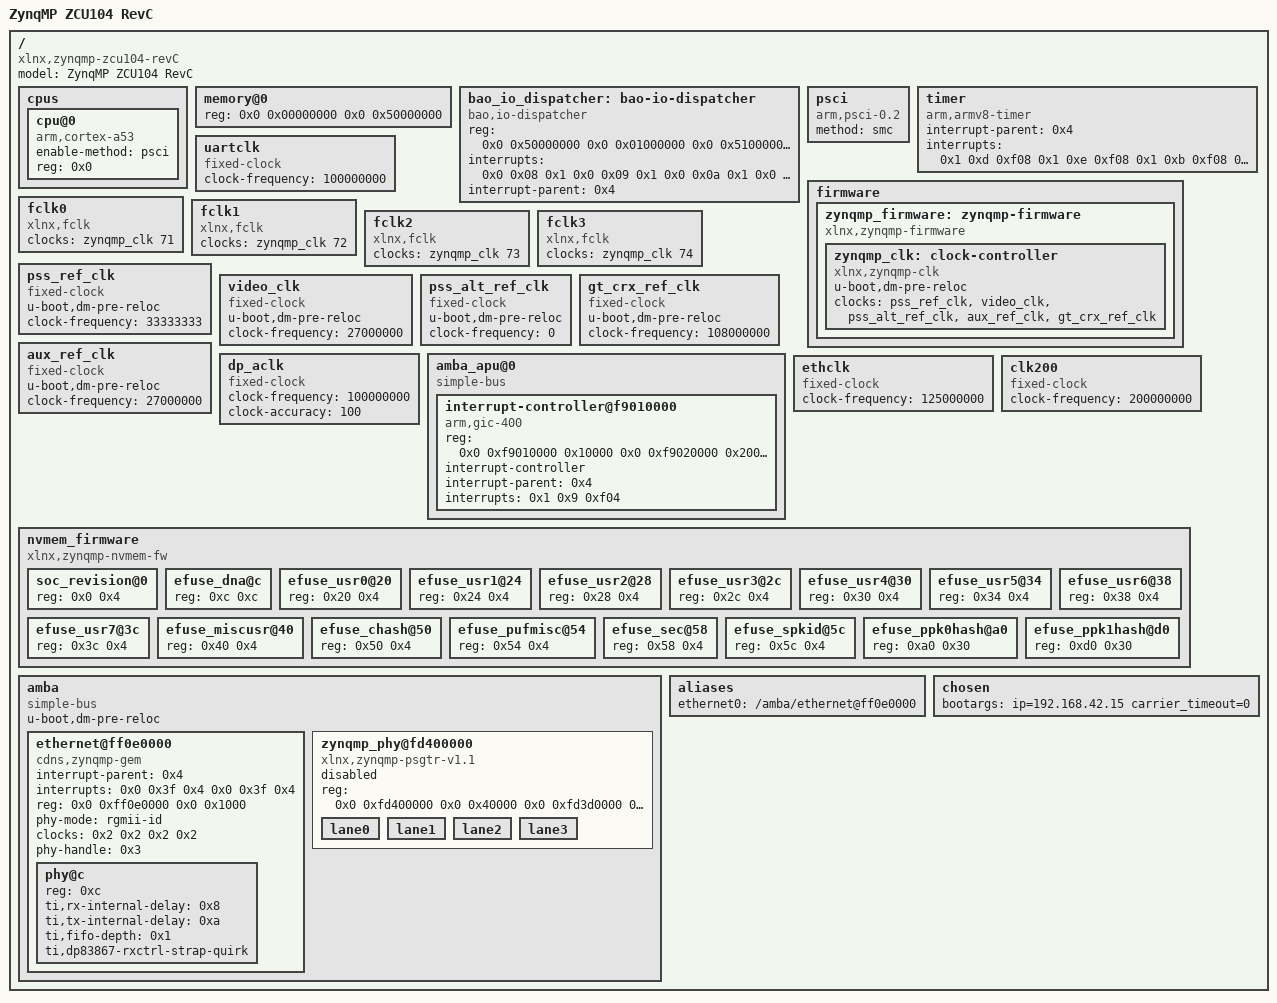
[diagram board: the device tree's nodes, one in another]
/dts-v1/;

/ {
	compatible = "xlnx,zynqmp-zcu104-revC", "xlnx,zynqmp-zcu104", "xlnx,zynqmp";
	#address-cells = <0x2>;
	#size-cells = <0x2>;
	model = "ZynqMP ZCU104 RevC";

	cpus {
		#size-cells = <0x0>;
		#address-cells = <0x1>;

		cpu@0 {
			compatible = "arm,cortex-a53", "arm,armv8";
			device_type = "cpu";
			enable-method = "psci";
			reg = <0x0>;
		};
	};

    memory@0 {
		device_type = "memory"; 
		reg = <0x0 0x00000000 0x0 0x50000000>;
	};

	bao_io_dispatcher: bao-io-dispatcher {
		compatible = "bao,io-dispatcher";
		reg = <0x0 0x50000000 0x0 0x01000000
			   0x0 0x51000000 0x0 0x01000000
			   0x0 0x52000000 0x0 0x01000000
			   0x0 0x53000000 0x0 0x01000000
			   0x0 0x54000000 0x0 0x01000000>;
		interrupts = <0x0 0x08 0x1
					  0x0 0x09 0x1
					  0x0 0x0a 0x1
					  0x0 0x0b 0x1
					  0x0 0x0c 0x1>;
		interrupt-parent = <0x4>;
	};

	psci {
		compatible = "arm,psci-0.2";
		method = "smc";
	};

	timer {
		compatible = "arm,armv8-timer";
		interrupt-parent = <0x4>;
		interrupts = <0x1 0xd 0xf08 0x1 0xe 0xf08 0x1 0xb 0xf08 0x1 0xa 0xf08>;
	};

	uartclk: uartclk {
		compatible = "fixed-clock";
		#clock-cells = <0x0>;
		clock-frequency = <100000000>;
		phandle = <0x1>;
	};

	firmware {
		zynqmp_firmware: zynqmp-firmware {
            compatible = "xlnx,zynqmp-firmware";
            zynqmp_clk: clock-controller {
                u-boot,dm-pre-reloc;
                #clock-cells = <1>;
                compatible = "xlnx,zynqmp-clk";
                clocks = <&pss_ref_clk>, <&video_clk>, <&pss_alt_ref_clk>,
                    <&aux_ref_clk>, <&gt_crx_ref_clk>;
                clock-names = "pss_ref_clk", "video_clk", "pss_alt_ref_clk",
                        "aux_ref_clk", "gt_crx_ref_clk";
            };
		};
	};

    fclk0: fclk0 {
        status = "okay";
        compatible = "xlnx,fclk";
        clocks = <&zynqmp_clk 71>;
    };

    fclk1: fclk1 {
        status = "okay";
        compatible = "xlnx,fclk";
        clocks = <&zynqmp_clk 72>;
    };

    fclk2: fclk2 {
        status = "okay";
        compatible = "xlnx,fclk";
        clocks = <&zynqmp_clk 73>;
    };

    fclk3: fclk3 {
        status = "okay";
        compatible = "xlnx,fclk";
        clocks = <&zynqmp_clk 74>;
    };

    pss_ref_clk: pss_ref_clk {
        u-boot,dm-pre-reloc;
        compatible = "fixed-clock";
        #clock-cells = <0>;
        clock-frequency = <33333333>;
    };

    video_clk: video_clk {
        u-boot,dm-pre-reloc;
        compatible = "fixed-clock";
        #clock-cells = <0>;
        clock-frequency = <27000000>;
    };

    pss_alt_ref_clk: pss_alt_ref_clk {
        u-boot,dm-pre-reloc;
        compatible = "fixed-clock";
        #clock-cells = <0>;
        clock-frequency = <0>;
    };

    gt_crx_ref_clk: gt_crx_ref_clk {
        u-boot,dm-pre-reloc;
        compatible = "fixed-clock";
        #clock-cells = <0>;
        clock-frequency = <108000000>;
    };

    aux_ref_clk: aux_ref_clk {
        u-boot,dm-pre-reloc;
        compatible = "fixed-clock";
        #clock-cells = <0>;
        clock-frequency = <27000000>;
    };

    dp_aclk: dp_aclk {
        compatible = "fixed-clock";
        #clock-cells = <0>;
        clock-frequency = <100000000>;
        clock-accuracy = <100>;
    };

	amba_apu@0 {
		compatible = "simple-bus";
		#address-cells = <0x2>;
		#size-cells = <0x1>;
		ranges = <0x0 0x0 0x0 0x0 0xffffffff>;

		interrupt-controller@f9010000 {
			compatible = "arm,gic-400", "arm,cortex-a15-gic";
			#interrupt-cells = <0x3>;
			reg = <0x0 0xf9010000 0x10000 0x0 0xf9020000 0x20000 0x0 0xf9040000 0x20000 0x0 0xf9060000 0x20000>;
			interrupt-controller;
			interrupt-parent = <0x4>;
			interrupts = <0x1 0x9 0xf04>;
			phandle = <0x4>;
		};
	};

	ethclk: ethclk {
		compatible = "fixed-clock";
		#clock-cells = <0x0>;
		clock-frequency = <125000000>;
		phandle = <0x2>;
	};

    clk200: clk200 {
		compatible = "fixed-clock";
		#clock-cells = <0x0>;
		clock-frequency = <200000000>;
	};


	nvmem_firmware {
		compatible = "xlnx,zynqmp-nvmem-fw";
		#address-cells = <0x1>;
		#size-cells = <0x1>;

		soc_revision@0 {
			reg = <0x0 0x4>;
			phandle = <0x16>;
		};

		efuse_dna@c {
			reg = <0xc 0xc>;
		};

		efuse_usr0@20 {
			reg = <0x20 0x4>;
		};

		efuse_usr1@24 {
			reg = <0x24 0x4>;
		};

		efuse_usr2@28 {
			reg = <0x28 0x4>;
		};

		efuse_usr3@2c {
			reg = <0x2c 0x4>;
		};

		efuse_usr4@30 {
			reg = <0x30 0x4>;
		};

		efuse_usr5@34 {
			reg = <0x34 0x4>;
		};

		efuse_usr6@38 {
			reg = <0x38 0x4>;
		};

		efuse_usr7@3c {
			reg = <0x3c 0x4>;
		};

		efuse_miscusr@40 {
			reg = <0x40 0x4>;
		};

		efuse_chash@50 {
			reg = <0x50 0x4>;
		};

		efuse_pufmisc@54 {
			reg = <0x54 0x4>;
		};

		efuse_sec@58 {
			reg = <0x58 0x4>;
		};

		efuse_spkid@5c {
			reg = <0x5c 0x4>;
		};

		efuse_ppk0hash@a0 {
			reg = <0xa0 0x30>;
		};

		efuse_ppk1hash@d0 {
			reg = <0xd0 0x30>;
		};
	};

	amba {
		compatible = "simple-bus";
		u-boot,dm-pre-reloc;
		#address-cells = <0x2>;
		#size-cells = <0x2>;
		ranges;

		ethernet@ff0e0000 {
			compatible = "cdns,zynqmp-gem", "cdns,gem";
			status = "okay";
			interrupt-parent = <0x4>;
			interrupts = <0x0 0x3f 0x4 0x0 0x3f 0x4>;
			reg = <0x0 0xff0e0000 0x0 0x1000>;
			clock-names = "pclk", "hclk", "tx_clk", "rx_clk";
			phy-mode = "rgmii-id";
			#address-cells = <0x1>;
			#size-cells = <0x0>;
			clocks = <0x2 0x2 0x2 0x2>;
			phy-handle = <0x3>;

			phy@c {
				reg = <0xc>;
				ti,rx-internal-delay = <0x8>;
				ti,tx-internal-delay = <0xa>;
				ti,fifo-depth = <0x1>;
				ti,dp83867-rxctrl-strap-quirk;
				phandle = <0x3>;
			};
		};

		zynqmp_phy@fd400000 {
			compatible = "xlnx,zynqmp-psgtr-v1.1";
			status = "disabled";
			reg = <0x0 0xfd400000 0x0 0x40000 0x0 0xfd3d0000 0x0 0x1000>;
			reg-names = "serdes", "siou";

			lane0 {
				#phy-cells = <0x4>;
			};

			lane1 {
				#phy-cells = <0x4>;
			};

			lane2 {
				#phy-cells = <0x4>;
			};

			lane3 {
				#phy-cells = <0x4>;
			};
		};
	};

	aliases {
		ethernet0 = "/amba/ethernet@ff0e0000";
	};

	chosen {
		bootargs = "ip=192.168.42.15 carrier_timeout=0";
	};
};
